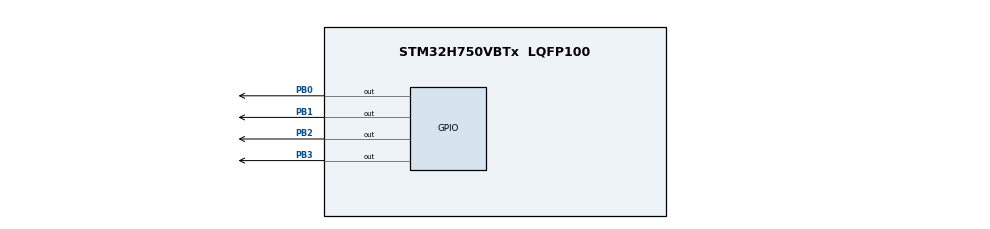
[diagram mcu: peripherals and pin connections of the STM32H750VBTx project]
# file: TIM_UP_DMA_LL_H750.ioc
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Dma.Request0=TIM3_UP
Dma.TIM3_UP.0.Direction=DMA_MEMORY_TO_PERIPH
Dma.TIM3_UP.0.EventEnable=DISABLE
Dma.TIM3_UP.0.FIFOMode=DMA_FIFOMODE_DISABLE
Dma.TIM3_UP.0.Instance=DMA1_Stream0
Dma.TIM3_UP.0.MemDataAlignment=DMA_MDATAALIGN_WORD
Dma.TIM3_UP.0.MemInc=DMA_MINC_ENABLE
Dma.TIM3_UP.0.Mode=DMA_CIRCULAR
Dma.TIM3_UP.0.PeriphDataAlignment=DMA_PDATAALIGN_WORD
Dma.TIM3_UP.0.PeriphInc=DMA_PINC_DISABLE
Dma.TIM3_UP.0.Polarity=HAL_DMAMUX_REQ_GEN_RISING
Dma.TIM3_UP.0.Priority=DMA_PRIORITY_LOW
Dma.TIM3_UP.0.RequestNumber=1
Dma.TIM3_UP.0.SignalID=NONE
Dma.TIM3_UP.0.SyncEnable=DISABLE
Dma.TIM3_UP.0.SyncPolarity=HAL_DMAMUX_SYNC_NO_EVENT
Dma.TIM3_UP.0.SyncRequestNumber=1
Dma.TIM3_UP.0.SyncSignalID=NONE
Mcu.Family=STM32H7
Mcu.Name=STM32H750VBTx
Mcu.Package=LQFP100
NVIC.DMA1_Stream0_IRQn=true\:0\:0\:false\:false\:true\:false\:true\:true
NVIC.PriorityGroup=NVIC_PRIORITYGROUP_4
PA13\ (JTMS/SWDIO).Mode=Serial_Wire
PA13\ (JTMS/SWDIO).Signal=DEBUG_JTMS-SWDIO
PA14\ (JTCK/SWCLK).Mode=Serial_Wire
PA14\ (JTCK/SWCLK).Signal=DEBUG_JTCK-SWCLK
PB0.Signal=GPIO_Output
PB1.Signal=GPIO_Output
PB2.Signal=GPIO_Output
PB3\ (JTDO/TRACESWO).Signal=GPIO_Output
PH0-OSC_IN\ (PH0).Mode=HSE-External-Oscillator
PH0-OSC_IN\ (PH0).Signal=RCC_OSC_IN
PH1-OSC_OUT\ (PH1).Mode=HSE-External-Oscillator
PH1-OSC_OUT\ (PH1).Signal=RCC_OSC_OUT
ProjectManager.HeapSize=0x200
ProjectManager.StackSize=0x400
ProjectManager.TargetToolchain=STM32CubeIDE
RCC.ADCFreq_Value=50390625
RCC.APB1Freq_Value=120000000
RCC.APB2Freq_Value=120000000
RCC.APB3Freq_Value=120000000
RCC.APB4Freq_Value=120000000
RCC.CortexFreq_Value=240000000
RCC.DIVM1=25
RCC.DIVN1=480
RCC.HCLKFreq_Value=120000000
RCC.HPRE=RCC_HCLK_DIV2
RCC.PLLSourceVirtual=RCC_PLLSOURCE_HSE
RCC.SYSCLKFreq_VALUE=240000000
RCC.SYSCLKSource=RCC_SYSCLKSOURCE_PLLCLK
RCC.USBFreq_Value=240000000
TIM3.AutoReloadPreload=TIM_AUTORELOAD_PRELOAD_ENABLE
TIM3.Period=999
TIM3.Prescaler=119
VP_TIM3_VS_ClockSourceINT.Mode=Internal
board=custom

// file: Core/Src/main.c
/* USER CODE BEGIN Header */
/**
  ******************************************************************************
  * @file           : main.c
  * @brief          : Main program body
  ******************************************************************************
  * @attention
  *
  * Copyright (c) 2023 STMicroelectronics.
  * All rights reserved.
  *
  * This software is licensed under terms that can be found in the LICENSE file
  * in the root directory of this software component.
  * If no LICENSE file comes with this software, it is provided AS-IS.
  *
  ******************************************************************************
  */
/* USER CODE END Header */
#include "main.h"

void SystemClock_Config(void);
static void MX_GPIO_Init(void);
static void MX_DMA_Init(void);
static void MX_TIM3_Init(void);

int main(void)
{

  /* MCU Configuration--------------------------------------------------------*/

  /* Reset of all peripherals, Initializes the Flash interface and the Systick. */
  LL_APB4_GRP1_EnableClock(LL_APB4_GRP1_PERIPH_SYSCFG);

  /* System interrupt init*/
  NVIC_SetPriorityGrouping(NVIC_PRIORITYGROUP_4);

  /* SysTick_IRQn interrupt configuration */
  NVIC_SetPriority(SysTick_IRQn, NVIC_EncodePriority(NVIC_GetPriorityGrouping(),15, 0));

  /* Configure the system clock */
  SystemClock_Config();

  /* Initialize all configured peripherals */
  MX_GPIO_Init();
  MX_DMA_Init();
  MX_TIM3_Init();

  /* Infinite loop */
  /* USER CODE BEGIN WHILE */

  // BSRR寄存器数据，高16位用于清除端口，低16位用于设置端口
  uint32_t buff[5] ={0x000F0000, 0x00000008, 0x00000004, 0x00000002, 0x00000001};

  LL_DMA_SetPeriphAddress(DMA1, LL_DMA_STREAM_0, (uint32_t)&GPIOB->BSRR); // 设置外设地址
  LL_DMA_SetMemoryAddress(DMA1, LL_DMA_STREAM_0, (uint32_t)&buff); // 设备内存地址
  LL_DMA_SetDataLength(DMA1, LL_DMA_STREAM_0, 5); // 设置传输长度

//  LL_DMA_EnableIT_TC(DMA1, LL_DMA_STREAM_0); // 开启传输完成中断
//  LL_DMA_EnableIT_TE(DMA1, LL_DMA_STREAM_0); // 开启传输错误中断

  LL_DMA_EnableStream(DMA1, LL_DMA_STREAM_0); // 开启DMA传输

  LL_TIM_EnableDMAReq_UPDATE(TIM3); // 使能TIM_UP请求DMA

  LL_TIM_EnableCounter(TIM3); // 启动定时器

  while (1)
  {
    /* USER CODE END WHILE */

  }
}

void SystemClock_Config(void)
{
  LL_FLASH_SetLatency(LL_FLASH_LATENCY_2);
  while(LL_FLASH_GetLatency()!= LL_FLASH_LATENCY_2)
  {
  }
  LL_PWR_ConfigSupply(LL_PWR_LDO_SUPPLY);
  LL_PWR_SetRegulVoltageScaling(LL_PWR_REGU_VOLTAGE_SCALE2);
  while (LL_PWR_IsActiveFlag_VOS() == 0)
  {
  }
  LL_RCC_HSE_Enable();

   /* Wait till HSE is ready */
  while(LL_RCC_HSE_IsReady() != 1)
  {

  }
  LL_RCC_PLL_SetSource(LL_RCC_PLLSOURCE_HSE);
  LL_RCC_PLL1P_Enable();
  LL_RCC_PLL1R_Enable();
  LL_RCC_PLL1_SetVCOInputRange(LL_RCC_PLLINPUTRANGE_1_2);
  LL_RCC_PLL1_SetVCOOutputRange(LL_RCC_PLLVCORANGE_WIDE);
  LL_RCC_PLL1_SetM(25);
  LL_RCC_PLL1_SetN(480);
  LL_RCC_PLL1_SetP(2);
  LL_RCC_PLL1_SetQ(2);
  LL_RCC_PLL1_SetR(2);
  LL_RCC_PLL1_Enable();

   /* Wait till PLL is ready */
  while(LL_RCC_PLL1_IsReady() != 1)
  {
  }

   /* Intermediate AHB prescaler 2 when target frequency clock is higher than 80 MHz */
   LL_RCC_SetAHBPrescaler(LL_RCC_AHB_DIV_2);

  LL_RCC_SetSysClkSource(LL_RCC_SYS_CLKSOURCE_PLL1);

   /* Wait till System clock is ready */
  while(LL_RCC_GetSysClkSource() != LL_RCC_SYS_CLKSOURCE_STATUS_PLL1)
  {

  }
  LL_RCC_SetSysPrescaler(LL_RCC_SYSCLK_DIV_1);
  LL_RCC_SetAHBPrescaler(LL_RCC_AHB_DIV_2);
  LL_RCC_SetAPB1Prescaler(LL_RCC_APB1_DIV_1);
  LL_RCC_SetAPB2Prescaler(LL_RCC_APB2_DIV_1);
  LL_RCC_SetAPB3Prescaler(LL_RCC_APB3_DIV_1);
  LL_RCC_SetAPB4Prescaler(LL_RCC_APB4_DIV_1);

  LL_Init1msTick(240000000);

  LL_SetSystemCoreClock(240000000);
}

static void MX_TIM3_Init(void)
{

  LL_TIM_InitTypeDef TIM_InitStruct = {0};

  /* Peripheral clock enable */
  LL_APB1_GRP1_EnableClock(LL_APB1_GRP1_PERIPH_TIM3);

  /* TIM3 DMA Init */

  /* TIM3_UP Init */
  LL_DMA_SetPeriphRequest(DMA1, LL_DMA_STREAM_0, LL_DMAMUX1_REQ_TIM3_UP);

  LL_DMA_SetDataTransferDirection(DMA1, LL_DMA_STREAM_0, LL_DMA_DIRECTION_MEMORY_TO_PERIPH);

  LL_DMA_SetStreamPriorityLevel(DMA1, LL_DMA_STREAM_0, LL_DMA_PRIORITY_LOW);

  LL_DMA_SetMode(DMA1, LL_DMA_STREAM_0, LL_DMA_MODE_CIRCULAR);

  LL_DMA_SetPeriphIncMode(DMA1, LL_DMA_STREAM_0, LL_DMA_PERIPH_NOINCREMENT);

  LL_DMA_SetMemoryIncMode(DMA1, LL_DMA_STREAM_0, LL_DMA_MEMORY_INCREMENT);

  LL_DMA_SetPeriphSize(DMA1, LL_DMA_STREAM_0, LL_DMA_PDATAALIGN_WORD);

  LL_DMA_SetMemorySize(DMA1, LL_DMA_STREAM_0, LL_DMA_MDATAALIGN_WORD);

  LL_DMA_DisableFifoMode(DMA1, LL_DMA_STREAM_0);

  TIM_InitStruct.Prescaler = 119;
  TIM_InitStruct.CounterMode = LL_TIM_COUNTERMODE_UP;
  TIM_InitStruct.Autoreload = 999;
  TIM_InitStruct.ClockDivision = LL_TIM_CLOCKDIVISION_DIV1;
  LL_TIM_Init(TIM3, &TIM_InitStruct);
  LL_TIM_EnableARRPreload(TIM3);
  LL_TIM_SetClockSource(TIM3, LL_TIM_CLOCKSOURCE_INTERNAL);
  LL_TIM_SetTriggerOutput(TIM3, LL_TIM_TRGO_RESET);
  LL_TIM_DisableMasterSlaveMode(TIM3);

}

static void MX_DMA_Init(void)
{

  /* Init with LL driver */
  /* DMA controller clock enable */
  LL_AHB1_GRP1_EnableClock(LL_AHB1_GRP1_PERIPH_DMA1);

  /* DMA interrupt init */
  /* DMA1_Stream0_IRQn interrupt configuration */
  NVIC_SetPriority(DMA1_Stream0_IRQn, NVIC_EncodePriority(NVIC_GetPriorityGrouping(),0, 0));
  NVIC_EnableIRQ(DMA1_Stream0_IRQn);

}

static void MX_GPIO_Init(void)
{
  LL_GPIO_InitTypeDef GPIO_InitStruct = {0};

  /* GPIO Ports Clock Enable */
  LL_AHB4_GRP1_EnableClock(LL_AHB4_GRP1_PERIPH_GPIOH);
  LL_AHB4_GRP1_EnableClock(LL_AHB4_GRP1_PERIPH_GPIOB);
  LL_AHB4_GRP1_EnableClock(LL_AHB4_GRP1_PERIPH_GPIOA);

  /**/
  LL_GPIO_ResetOutputPin(GPIOB, LL_GPIO_PIN_0|LL_GPIO_PIN_1|LL_GPIO_PIN_2|LL_GPIO_PIN_3);

  /**/
  GPIO_InitStruct.Pin = LL_GPIO_PIN_0|LL_GPIO_PIN_1|LL_GPIO_PIN_2|LL_GPIO_PIN_3;
  GPIO_InitStruct.Mode = LL_GPIO_MODE_OUTPUT;
  GPIO_InitStruct.Speed = LL_GPIO_SPEED_FREQ_LOW;
  GPIO_InitStruct.OutputType = LL_GPIO_OUTPUT_PUSHPULL;
  GPIO_InitStruct.Pull = LL_GPIO_PULL_NO;
  LL_GPIO_Init(GPIOB, &GPIO_InitStruct);

}

void Error_Handler(void)
{
  __disable_irq();
  while (1)
  {
  }
}
